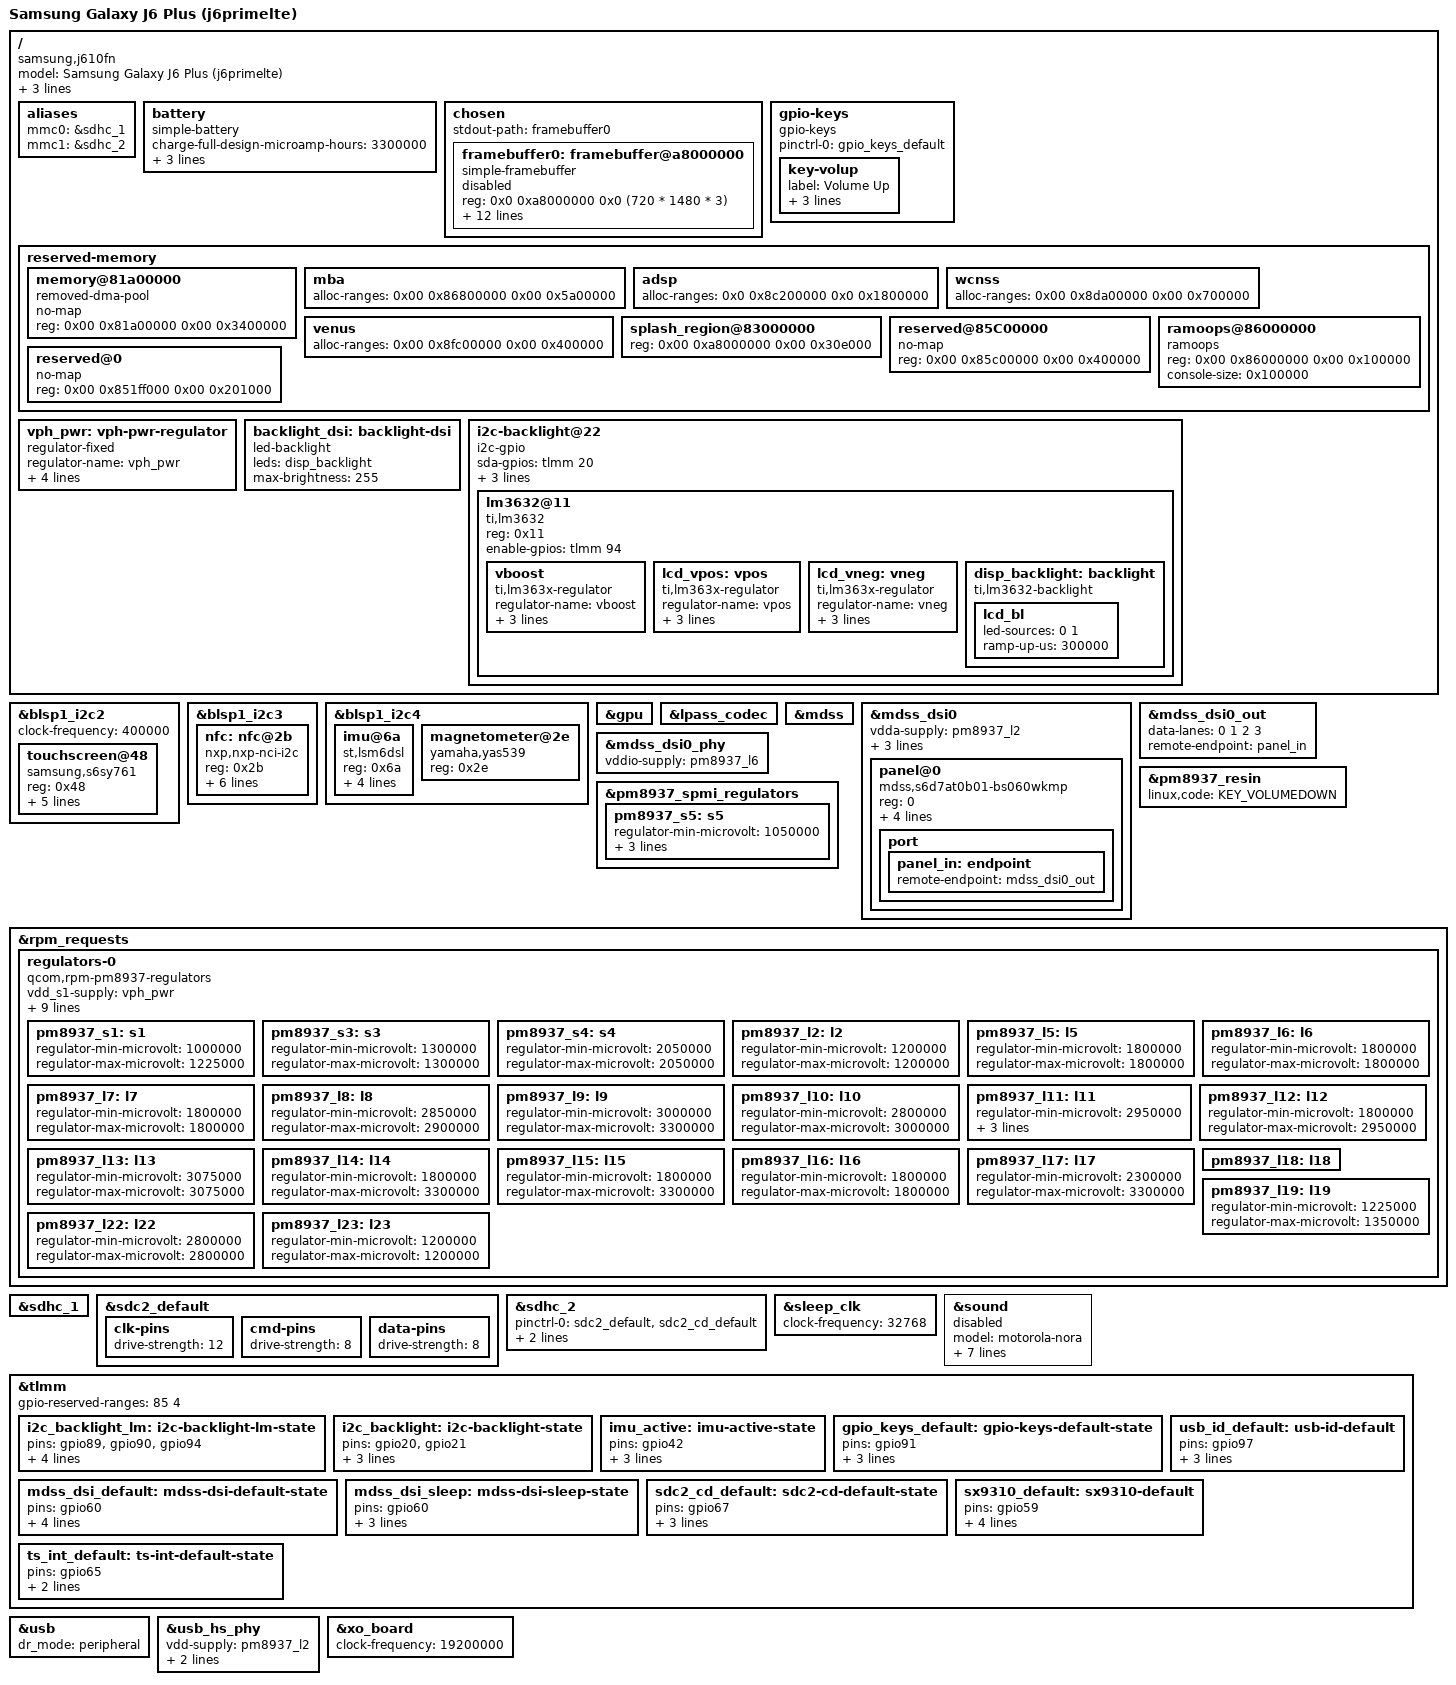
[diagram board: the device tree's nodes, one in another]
// SPDX-License-Identifier: BSD-3-Clause
/*
 * Copyright (c) 2025 Val Packett
 */

/dts-v1/;

#include <dt-bindings/arm/qcom,ids.h>
#include <dt-bindings/gpio/gpio.h>
#include <dt-bindings/leds/common.h>
#include "msm8917.dtsi"
#include "pm8937.dtsi"
#include "msm8937-qdsp6.dtsi"

/delete-node/ &qseecom_mem;

/ {
	model = "Samsung Galaxy J6 Plus (j6primelte)";
	compatible = "samsung,j610fn", "qcom,msm8917";
	qcom,msm-id = <QCOM_ID_MSM8917 0>;
	qcom,board-id = <0x08 0x06>;
	chassis-type = "handset";

	aliases {
		mmc0 = &sdhc_1;
		mmc1 = &sdhc_2;
	};

	battery: battery {
		compatible = "simple-battery";

		charge-full-design-microamp-hours = <3300000>;
		constant-charge-current-max-microamp = <1000000>;
		voltage-min-design-microvolt = <3400000>;
		voltage-max-design-microvolt = <4400000>;
	};

	chosen {
		#address-cells = <2>;
		#size-cells = <2>;
		ranges;

		stdout-path = "framebuffer0";

		framebuffer0: framebuffer@a8000000 {
			compatible = "simple-framebuffer";
			reg = <0x0 0xa8000000 0x0 (720 * 1480 * 3)>;
			width = <720>;
			height = <1480>;
			stride = <(720 * 3)>;
			format = "r8g8b8";

			clocks = <&gcc GCC_MDSS_AHB_CLK>,
				 <&gcc GCC_MDSS_AXI_CLK>,
				 <&gcc GCC_MDSS_VSYNC_CLK>,
				 <&gcc GCC_MDSS_MDP_CLK>,
				 <&gcc GCC_MDSS_BYTE0_CLK>,
				 <&gcc GCC_MDSS_PCLK0_CLK>,
				 <&gcc GCC_MDSS_ESC0_CLK>;
			power-domains = <&gcc MDSS_GDSC>;
			status = "disabled";
		};
	};

	gpio-keys {
		compatible = "gpio-keys";

		pinctrl-0 = <&gpio_keys_default>;
		pinctrl-names = "default";

		key-volup {
			label = "Volume Up";
			linux,code = <KEY_VOLUMEUP>;
			gpios = <&tlmm 127 GPIO_ACTIVE_LOW>;
			debounce-interval = <15>;
		};
	};

	reserved-memory {
		
		/* Trustlet region */
		memory@81a00000{
			compatible = "removed-dma-pool";
			no-map;
			reg = <0x00 0x81a00000 0x00 0x3400000>;
		};

		mba {
			alloc-ranges = <0x00 0x86800000 0x00 0x5a00000>;
		};

		adsp {
			alloc-ranges = <0x0 0x8c200000 0x0 0x1800000>;
		};

		wcnss {
			alloc-ranges = <0x00 0x8da00000 0x00 0x700000>;
		};

		venus {

			alloc-ranges = <0x00 0x8fc00000 0x00 0x400000>;
		};

		splash_region@83000000 {
			reg = <0x00 0xa8000000 0x00 0x30e000>;
		};

		reserved@85C00000 {
			no-map;
			reg = <0x00 0x85c00000 0x00 0x400000>;
		};

		ramoops@86000000 {
			compatible = "ramoops";
			reg = <0x00 0x86000000 0x00 0x100000>;
			console-size = <0x100000>;
		};

		reserved@0 {
			no-map;
			reg = <0x00 0x851ff000 0x00 0x201000>;
		};
	};

	vph_pwr: vph-pwr-regulator {
		compatible = "regulator-fixed";
		regulator-name = "vph_pwr";
		regulator-min-microvolt = <3700000>;
		regulator-max-microvolt = <3700000>;
		regulator-always-on;
		regulator-boot-on;
	};
/* usb_id todo */

backlight_dsi: backlight-dsi {
		compatible = "led-backlight";
		leds = <&disp_backlight>;
		max-brightness = <255>;

	};

i2c-backlight@22 {

	compatible = "i2c-gpio";
	sda-gpios = <&tlmm 20 (GPIO_ACTIVE_HIGH|GPIO_OPEN_DRAIN)>;
	scl-gpios = <&tlmm 21 (GPIO_ACTIVE_HIGH|GPIO_OPEN_DRAIN)>;
	i2c-gpio,delay-us = <2>; /* ~100 kHz */
	pinctrl = <&i2c_backlight>;
	pinctrl-names = "default";
	#address-cells = <1>;
	#size-cells = <0>;

	lm3632@11 {
		compatible = "ti,lm3632";
		reg = <0x11>;
		#address-cells = <1>;
	#size-cells = <0>;
		enable-gpios = <&tlmm 94 GPIO_ACTIVE_HIGH>;

		vboost {
			compatible = "ti,lm363x-regulator";
			regulator-name = "vboost";
			regulator-min-microvolt = <5950000>;
			regulator-max-microvolt = <5950000>;
			regulator-always-on;
		};

		lcd_vpos: vpos  {
		 	compatible = "ti,lm363x-regulator";
			regulator-name = "vpos";
			regulator-min-microvolt = <5700000>;
			regulator-max-microvolt = <5700000>;
			enable-gpios = <&tlmm 89 GPIO_ACTIVE_HIGH>;
		};

		 lcd_vneg: vneg  {
		 	compatible = "ti,lm363x-regulator";
			regulator-name = "vneg";
			regulator-min-microvolt = <5700000>;
			regulator-max-microvolt = <5700000>;
			enable-gpios = <&tlmm 90 GPIO_ACTIVE_HIGH>;
		};
	
	

	disp_backlight: backlight {
		compatible = "ti,lm3632-backlight";

		lcd_bl {
			led-sources = <0 1>;
			ramp-up-us = <300000>;
		};
	};
	};
};


};
/*
&adsp {
	status = "okay";
};

&adsp_mem {
	status = "okay";
};

&apr {
	status = "okay";
};
*/

&blsp1_i2c2 {
	clock-frequency = <400000>;
	status = "okay";
	
	touchscreen@48 {
		compatible = "samsung,s6sy761";
		reg = <0x48>;
		interrupts-extended = <&tlmm 65 IRQ_TYPE_EDGE_FALLING>;
		pinctrl-0 = <&ts_int_default>;
		pinctrl-names = "default";
		touchscreen-size-x = <4096>;
		touchscreen-size-y = <4096>;
	};

	// sec,ts@48
};

&blsp1_i2c3 {
	status = "okay";

	nfc: nfc@2b {
		compatible = "nxp,nxp-nci-i2c";

		reg = <0x2b>;

		interrupt-parent = <&tlmm>;
		interrupts = <46 IRQ_TYPE_LEVEL_HIGH>;

		pn547,det-gpio = <0x1b 0x61 0x00>; //97
		pn547,pvdd-gpio = <0x1b 0x81 0x00>; //129
		
		enable-gpios = <&tlmm 95 GPIO_ACTIVE_HIGH>;
		firmware-gpios = <&tlmm 41 GPIO_ACTIVE_HIGH>;

		pinctrl-names = "default";
		//pinctrl-0 = <&nfc_default>;
	};
};


&blsp1_i2c4 {
	status = "okay";

	imu@6a {
		compatible = "st,lsm6dsl";
		reg = <0x6a>;
		interrupt-parent = <&tlmm>;
		interrupts = <42 IRQ_TYPE_EDGE_RISING>;
		pinctrl = <&imu_active>;
		mount-matrix = "-1", "0", "0",
				"0", "-1", "0",
				"0", "0", "1";
	};

magnetometer@2e {
	compatible = "yamaha,yas539";
	reg = <0x2e>;
        };
        

	//cm36686@60 TODO
	
	//stk3328@68
};

&gpu {
	status = "okay";
};

&lpass_codec {
	status = "okay";
};

&mdss {
	status = "okay";
};

&mdss_dsi0 {
	vdda-supply = <&pm8937_l2>;
	vddio-supply = <&pm8937_l6>;
	
	pinctrl-0 = <&mdss_dsi_default>, <&i2c_backlight_lm>;
	pinctrl-1 = <&mdss_dsi_sleep>;
	pinctrl-names = "default", "sleep";

	status = "okay";

	panel@0 {
		compatible = "mdss,s6d7at0b01-bs060wkmp";
		reg = <0>;
		
		vsn-supply = <&lcd_vneg>;
		vsp-supply = <&lcd_vpos>;
		reset-gpios = <&tlmm 60 GPIO_ACTIVE_LOW>;
		backlight = <&disp_backlight>;

		port {
			panel_in: endpoint {
				remote-endpoint = <&mdss_dsi0_out>;
			};
		};
	};
};

&mdss_dsi0_out {
	data-lanes = <0 1 2 3>;
	remote-endpoint = <&panel_in>;
};

&mdss_dsi0_phy {
	vddio-supply = <&pm8937_l6>;
	status = "okay";
};

&pm8937_resin {
	linux,code = <KEY_VOLUMEDOWN>;
	status = "okay";
};

&pm8937_spmi_regulators {
	// PM8937 S5 + S6 = VDD_APC supply
	pm8937_s5: s5 {
		regulator-min-microvolt = <1050000>;
		regulator-max-microvolt = <1350000>;
		regulator-always-on;
		regulator-boot-on;
	};
};

&rpm_requests {
	regulators-0 {
		compatible = "qcom,rpm-pm8937-regulators";

		vdd_s1-supply = <&vph_pwr>;
		vdd_s2-supply = <&vph_pwr>;
		vdd_s3-supply = <&vph_pwr>;
		vdd_s4-supply = <&vph_pwr>;

		vdd_l1_l19-supply = <&pm8937_s3>;
		vdd_l2_l23-supply = <&pm8937_s3>;
		vdd_l3-supply = <&pm8937_s3>;
		vdd_l4_l5_l6_l7_l16-supply = <&pm8937_s4>;
		vdd_l8_l11_l12_l17_l22-supply = <&vph_pwr>;
		vdd_l9_l10_l13_l14_l15_l18-supply = <&vph_pwr>;

		pm8937_s1: s1 {
			regulator-min-microvolt = <1000000>;
			regulator-max-microvolt = <1225000>;
		};

		pm8937_s3: s3 {
			regulator-min-microvolt = <1300000>;
			regulator-max-microvolt = <1300000>;
		};

		pm8937_s4: s4 {
			regulator-min-microvolt = <2050000>;
			regulator-max-microvolt = <2050000>;
		};

		pm8937_l2: l2 {
			regulator-min-microvolt = <1200000>;
			regulator-max-microvolt = <1200000>;
		};

		pm8937_l5: l5 {
			regulator-min-microvolt = <1800000>;
			regulator-max-microvolt = <1800000>;
		};

		pm8937_l6: l6 {
			regulator-min-microvolt = <1800000>;
			regulator-max-microvolt = <1800000>;
		};

		pm8937_l7: l7 {
			regulator-min-microvolt = <1800000>;
			regulator-max-microvolt = <1800000>;
		};

		pm8937_l8: l8 {
			regulator-min-microvolt = <2850000>;
			regulator-max-microvolt = <2900000>;
		};

		pm8937_l9: l9 {
			regulator-min-microvolt = <3000000>;
			regulator-max-microvolt = <3300000>;
		};

		pm8937_l10: l10 {
			regulator-min-microvolt = <2800000>;
			regulator-max-microvolt = <3000000>;
		};

		pm8937_l11: l11 {
			regulator-min-microvolt = <2950000>;
			regulator-max-microvolt = <2950000>;
			regulator-allow-set-load;
			regulator-system-load = <200000>;
		};

		pm8937_l12: l12 {
			regulator-min-microvolt = <1800000>;
			regulator-max-microvolt = <2950000>;
		};

		pm8937_l13: l13 {
			regulator-min-microvolt = <3075000>;
			regulator-max-microvolt = <3075000>;
		};

		pm8937_l14: l14 {
			regulator-min-microvolt = <1800000>;
			regulator-max-microvolt = <3300000>;
		};

		pm8937_l15: l15 {
			regulator-min-microvolt = <1800000>;
			regulator-max-microvolt = <3300000>;
		};

		pm8937_l16: l16 {
			regulator-min-microvolt = <1800000>;
			regulator-max-microvolt = <1800000>;
		};

		pm8937_l17: l17 {
			regulator-min-microvolt = <2300000>;
			regulator-max-microvolt = <3300000>;
		};

		pm8937_l18: l18 {
			//regulator-min-microvolt = <2700000>;
			//regulator-max-microvolt = <2700000>;
		};

		pm8937_l19: l19 {
			regulator-min-microvolt = <1225000>;
			regulator-max-microvolt = <1350000>;
		};

		pm8937_l22: l22 {
			regulator-min-microvolt = <2800000>;
			regulator-max-microvolt = <2800000>;
		};

		pm8937_l23: l23 {
			regulator-min-microvolt = <1200000>;
			regulator-max-microvolt = <1200000>;
		};
	};
};

&sdhc_1 {
	status = "okay";
};


&sdc2_default {

clk-pins {
				
					drive-strength = <12>;
				};

				cmd-pins {
					
					drive-strength = <8>;
				};

				data-pins {
					
					drive-strength = <8>;
				};
};
&sdhc_2 {

	pinctrl-0 = <&sdc2_default &sdc2_cd_default>;
	pinctrl-1 = <&sdc2_default &sdc2_cd_default>;
	pinctrl-names = "default", "sleep";

	cd-gpios = <&tlmm 67 GPIO_ACTIVE_LOW>;

	status = "okay";
};

&sleep_clk {
	clock-frequency = <32768>;
};

&sound {
	model = "motorola-nora";
	audio-routing =
		"AMIC1", "MIC BIAS External1",
		"AMIC2", "MIC BIAS External2",
		"AMIC3", "MIC BIAS External1",
		"MM_DL1", "MultiMedia1 Playback",
		"MM_DL3", "MultiMedia3 Playback",
		"MM_DL4", "MultiMedia4 Playback",
		"MultiMedia2 Capture", "MM_UL2";

	status = "disabled";
};

&tlmm {
	gpio-reserved-ranges = <85 4>;


i2c_backlight_lm: i2c-backlight-lm-state {
pins = "gpio89", "gpio90", "gpio94";
		function = "gpio";
		drive-strength = <8>;
		bias-disable;
		output-high;

};

i2c_backlight: i2c-backlight-state {
pins = "gpio20", "gpio21";
		function = "gpio";
		drive-strength = <8>;
		bias-disable;
};

	imu_active:imu-active-state {
	pins = "gpio42";
		function = "gpio";
		drive-strength = <2>;
		bias-disable;
	};
	
	gpio_keys_default: gpio-keys-default-state {
		pins = "gpio91";
		function = "gpio";
		drive-strength = <2>;
		bias-pull-up;
	};

	mdss_dsi_default: mdss-dsi-default-state {
		pins = "gpio60";
		function = "gpio";
		drive-strength = <8>;
		bias-disable;
		output-high;
	};

	mdss_dsi_sleep: mdss-dsi-sleep-state {
		pins = "gpio60";
		function = "gpio";
		drive-strength = <2>;
		bias-pull-down;
	};

	sdc2_cd_default: sdc2-cd-default-state {
		pins = "gpio67";
		function = "gpio";
		drive-strength = <2>;
		bias-disable;
	};

	usb_id_default: usb-id-default {
		pins = "gpio97";
		function = "gpio";
		drive-strength = <8>;
		bias-pull-up;
	};

	sx9310_default: sx9310-default {
		pins = "gpio59";
		function = "gpio";
		drive-strength = <2>;
		bias-pull-up;
		input-enable;
	};
	ts_int_default: ts-int-default-state {
		pins = "gpio65";
		function = "gpio";
		bias-disable;
	};
};

&usb {
	dr_mode = "peripheral";
	//extcon = <&pmi8950_smbcharger>, <&usb_id>;
	//vbus-supply = <&otg_vbus>;
	status = "okay";
};

&usb_hs_phy {
	vdd-supply = <&pm8937_l2>;
	vdda1p8-supply = <&pm8937_l7>;
	vdda3p3-supply = <&pm8937_l13>;
	status = "okay";
};
/*
&wcnss {
	vddpx-supply = <&pm8937_l5>;
	status = "okay";
};

&wcnss_ctrl {
	firmware-name = "qcom/msm8917/motorola/nora/WCNSS_qcom_wlan_nv.bin";
};

&wcnss_iris {
	compatible = "qcom,wcn3620";
	vddxo-supply = <&pm8937_l7>;
	vddrfa-supply = <&pm8937_l19>;
	vddpa-supply = <&pm8937_l9>;
	vdddig-supply = <&pm8937_l5>;
};

&wcnss_mem {
status = "okay";
};

&wcd_codec {
	qcom,hphl-jack-type-normally-open;
	qcom,mbhc-vthreshold-high = <75 150 225 450 500>;
	qcom,mbhc-vthreshold-low = <75 150 225 450 500>;
	qcom,micbias1-ext-cap;

	vdd-cdc-io-supply = <&pm8937_l5>;
	vdd-cdc-tx-rx-cx-supply = <&pm8937_s4>;
	vdd-micbias-supply = <&pm8937_l13>;
	status = "okay";
};
*/

&xo_board {
	clock-frequency = <19200000>;
};


//imaginary i2c at pin 20&21
//ti,lm3632-backlight@11
//en 94
//enn 90
//enp 89

